# ESP32-H21 register map
Vendor: ESPRESSIF SYSTEMS (SHANGHAI) CO., LTD.; Series: ESP32 H-Series; File version: 1
CPU: RV32IMAC r0p0, little endian, no MPU, no FPU, 0 interrupt priority bits
Address unit: 32 bits
Registers are 32-bit, read-write, reset 0x0 unless marked. A register's access mark holds for its fields unless they carry their own. Offsets are from the block's base; [hi:lo] are bit positions; {n}, {i} and the like mark numbered series.

## LP_CLKRST — LP_CLKRST Peripheral
Base 0x600B0400
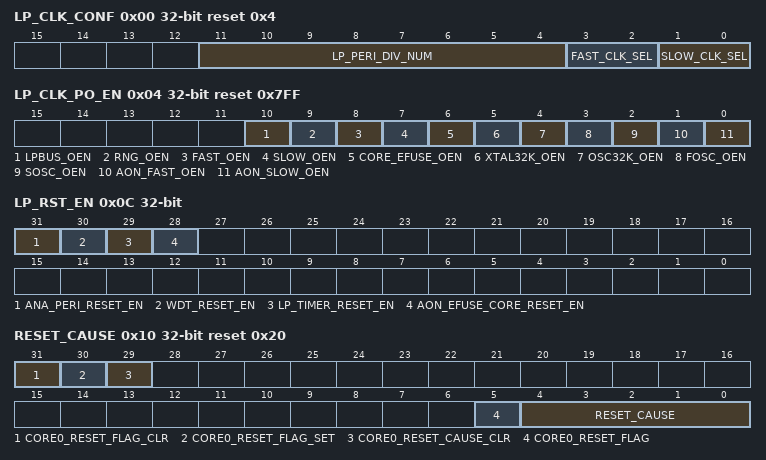
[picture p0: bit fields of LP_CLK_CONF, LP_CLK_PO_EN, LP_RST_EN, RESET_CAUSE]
0x00 LP_CLK_CONF reset 0x4 — need_des
  [11:4] LP_PERI_DIV_NUM — need_des
  [3:2] FAST_CLK_SEL — need_des
  [1:0] SLOW_CLK_SEL — need_des
0x04 LP_CLK_PO_EN reset 0x7FF — need_des
  [10] LPBUS_OEN — need_des
  [9] RNG_OEN — need_des
  [8] FAST_OEN — need_des
  [7] SLOW_OEN — need_des
  [6] CORE_EFUSE_OEN — need_des
  [5] XTAL32K_OEN — need_des
  [4] OSC32K_OEN — need_des
  [3] FOSC_OEN — need_des
  [2] SOSC_OEN — need_des
  [1] AON_FAST_OEN — need_des
  [0] AON_SLOW_OEN — need_des
0x08 LP_CLK_EN — need_des
  [31] FAST_ORI_GATE
0x0C LP_RST_EN — need_des
  [31] ANA_PERI_RESET_EN — need_des
  [30] WDT_RESET_EN — need_des
  [29] LP_TIMER_RESET_EN — need_des
  [28] AON_EFUSE_CORE_RESET_EN — need_des
0x10 RESET_CAUSE access per field reset 0x20 — need_des
  [31] CORE0_RESET_FLAG_CLR wo — need_des
  [30] CORE0_RESET_FLAG_SET wo — need_des
  [29] CORE0_RESET_CAUSE_CLR wo — need_des
  [5] CORE0_RESET_FLAG ro — need_des
  [4:0] RESET_CAUSE ro — need_des
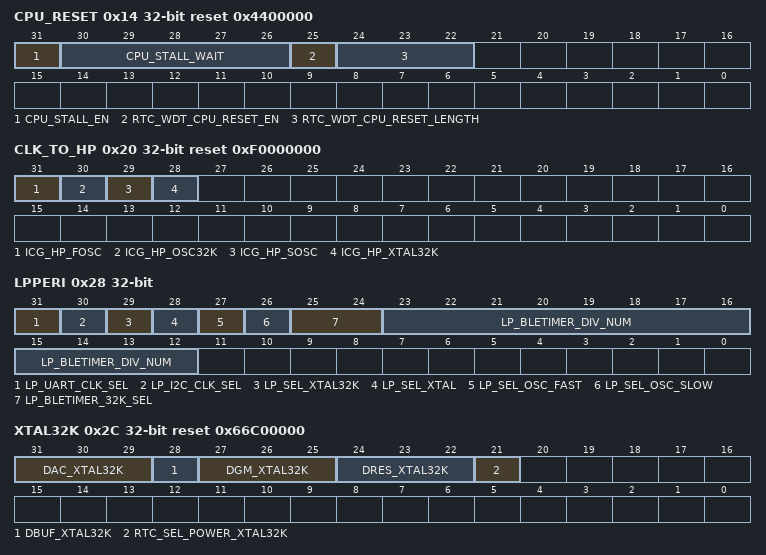
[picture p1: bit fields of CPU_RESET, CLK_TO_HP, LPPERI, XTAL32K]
0x14 CPU_RESET reset 0x4400000 — need_des
  [31] CPU_STALL_EN — need_des
  [30:26] CPU_STALL_WAIT — need_des
  [25] RTC_WDT_CPU_RESET_EN — need_des
  [24:22] RTC_WDT_CPU_RESET_LENGTH — need_des
0x18 FOSC_CNTL reset 0x96000000 — need_des
  [31:22] FOSC_DFREQ
0x1C RC32K_CNTL reset 0xA2800000 — need_des
  [31:22] RC32K_DFREQ
0x20 CLK_TO_HP reset 0xF0000000 — need_des
  [31] ICG_HP_FOSC — need_des
  [30] ICG_HP_OSC32K — need_des
  [29] ICG_HP_SOSC — need_des
  [28] ICG_HP_XTAL32K — need_des
0x24 LPMEM_FORCE — need_des
  [31] LPMEM_CLK_FORCE_ON
0x28 LPPERI — need_des
  [31] LP_UART_CLK_SEL — need_des
  [30] LP_I2C_CLK_SEL — need_des
  [29] LP_SEL_XTAL32K — need_des
  [28] LP_SEL_XTAL — need_des
  [27] LP_SEL_OSC_FAST — need_des
  [26] LP_SEL_OSC_SLOW — need_des
  [25:24] LP_BLETIMER_32K_SEL — need_des
  [23:12] LP_BLETIMER_DIV_NUM — need_des
0x2C XTAL32K reset 0x66C00000 — need_des
  [31:29] DAC_XTAL32K — need_des
  [28] DBUF_XTAL32K — need_des
  [27:25] DGM_XTAL32K — need_des
  [24:22] DRES_XTAL32K — need_des
  [21] RTC_SEL_POWER_XTAL32K — need_des
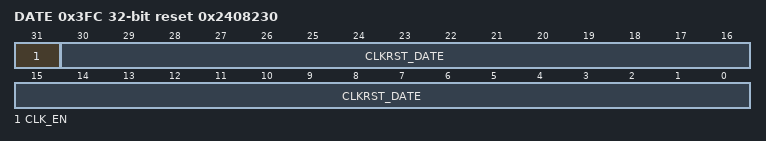
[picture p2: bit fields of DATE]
0x3FC DATE reset 0x2408230 — need_des
  [31] CLK_EN — need_des
  [30:0] CLKRST_DATE — need_des

## LP_TIMER — Low-power Timer
Base 0x600B0C00
0x00 TAR0_LOW — need_des
  [31:0] MAIN_TIMER_TAR_LOW0
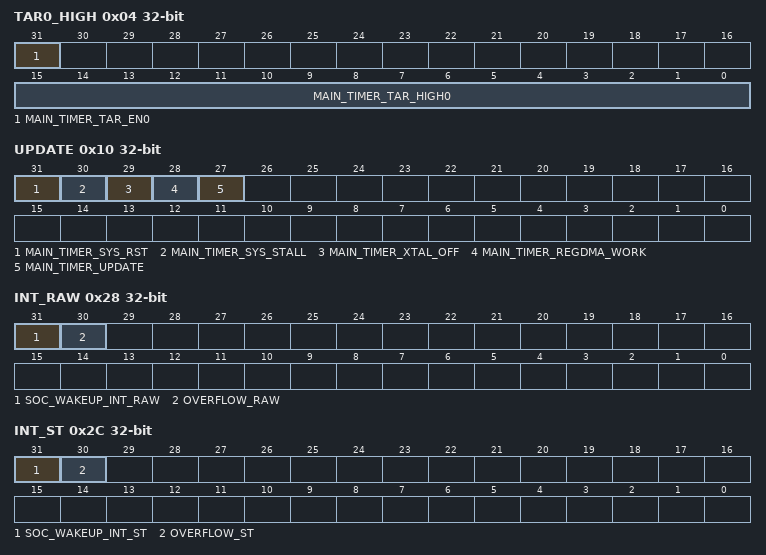
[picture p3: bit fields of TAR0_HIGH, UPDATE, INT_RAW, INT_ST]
0x04 TAR0_HIGH access per field — need_des
  [31] MAIN_TIMER_TAR_EN0 wo — need_des
  [15:0] MAIN_TIMER_TAR_HIGH0 rw — need_des
0x10 UPDATE access per field — need_des
  [31] MAIN_TIMER_SYS_RST rw — need_des
  [30] MAIN_TIMER_SYS_STALL rw — need_des
  [29] MAIN_TIMER_XTAL_OFF rw — need_des
  [28] MAIN_TIMER_REGDMA_WORK rw — Selects the triggering condition for the RTC timer,triggered when regdma working
  [27] MAIN_TIMER_UPDATE wo — need_des
0x14 MAIN_BUF0_LOW ro — need_des
  [31:0] MAIN_TIMER_BUF0_LOW
0x18 MAIN_BUF0_HIGH ro — need_des
  [15:0] MAIN_TIMER_BUF0_HIGH
0x1C MAIN_BUF1_LOW ro — need_des
  [31:0] MAIN_TIMER_BUF1_LOW
0x20 MAIN_BUF1_HIGH ro — need_des
  [15:0] MAIN_TIMER_BUF1_HIGH
0x24 MAIN_OVERFLOW wo — need_des
  [31] MAIN_TIMER_ALARM_LOAD
0x28 INT_RAW — need_des
  [31] SOC_WAKEUP_INT_RAW — need_des
  [30] OVERFLOW_RAW — need_des
0x2C INT_ST ro — need_des
  [31] SOC_WAKEUP_INT_ST — need_des
  [30] OVERFLOW_ST — need_des
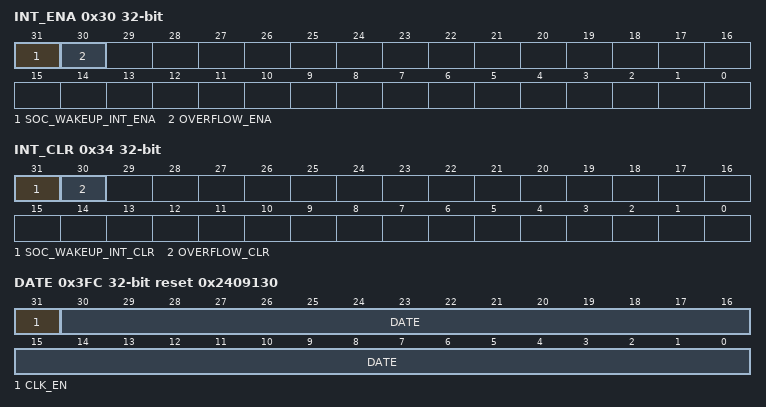
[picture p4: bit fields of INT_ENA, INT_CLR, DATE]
0x30 INT_ENA — need_des
  [31] SOC_WAKEUP_INT_ENA — need_des
  [30] OVERFLOW_ENA — need_des
0x34 INT_CLR wo — need_des
  [31] SOC_WAKEUP_INT_CLR — need_des
  [30] OVERFLOW_CLR — need_des
0x3FC DATE reset 0x2409130 — need_des
  [31] CLK_EN — need_des
  [30:0] DATE — need_des

## LP_WDT — Low-power Watchdog Timer
Base 0x600B1C00
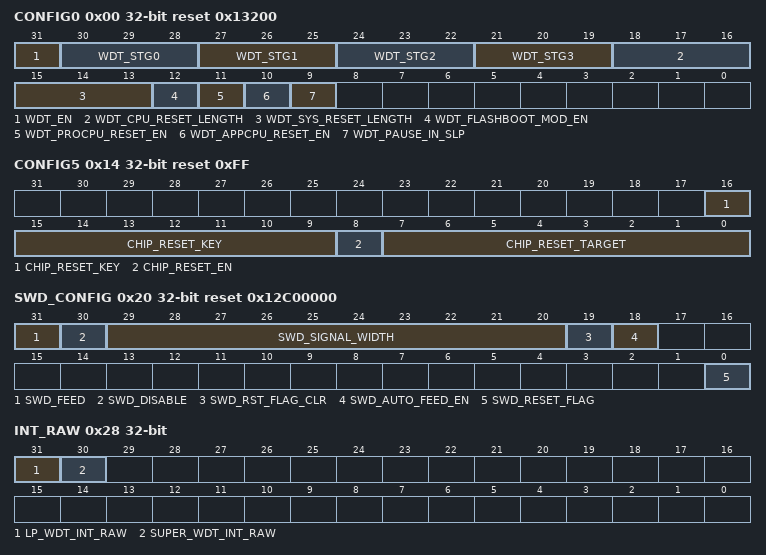
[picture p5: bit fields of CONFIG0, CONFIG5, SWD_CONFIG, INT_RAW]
0x00 CONFIG0 reset 0x13200 — need_des
  [31] WDT_EN — need_des
  [30-3n:28-3n] WDT_STG{n} (n=0..3) — need_des
  [18:16] WDT_CPU_RESET_LENGTH — need_des
  [15:13] WDT_SYS_RESET_LENGTH — need_des
  [12] WDT_FLASHBOOT_MOD_EN — need_des
  [11] WDT_PROCPU_RESET_EN — need_des
  [10] WDT_APPCPU_RESET_EN — need_des
  [9] WDT_PAUSE_IN_SLP — need_des
0x04 CONFIG1 reset 0x30D40 — need_des
  [31:0] WDT_STG0_HOLD
0x08 CONFIG2 reset 0x13880 — need_des
  [31:0] WDT_STG1_HOLD
0x0C CONFIG3 reset 0xFFF — need_des
  [31:0] WDT_STG2_HOLD
0x10 CONFIG4 reset 0xFFF — need_des
  [31:0] WDT_STG3_HOLD
0x14 CONFIG5 reset 0xFF — need_des
  [16:9] CHIP_RESET_KEY — need_des
  [8] CHIP_RESET_EN — need_des
  [7:0] CHIP_RESET_TARGET — need_des
0x18 FEED wo — need_des
  [31] RTC_WDT_FEED
0x1C WPROTECT — need_des
  [31:0] WDT_WKEY
0x20 SWD_CONFIG access per field reset 0x12C00000 — need_des
  [31] SWD_FEED wo — need_des
  [30] SWD_DISABLE rw — need_des
  [29:20] SWD_SIGNAL_WIDTH rw — need_des
  [19] SWD_RST_FLAG_CLR wo — need_des
  [18] SWD_AUTO_FEED_EN rw — need_des
  [0] SWD_RESET_FLAG ro — need_des
0x24 SWD_WPROTECT — need_des
  [31:0] SWD_WKEY
0x28 INT_RAW — need_des
  [31] LP_WDT_INT_RAW — need_des
  [30] SUPER_WDT_INT_RAW — need_des
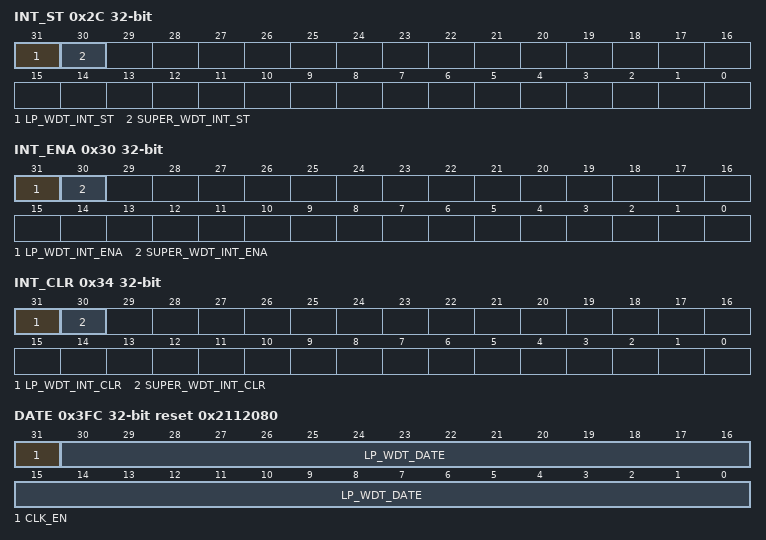
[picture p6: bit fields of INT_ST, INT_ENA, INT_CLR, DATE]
0x2C INT_ST ro — need_des
  [31] LP_WDT_INT_ST — need_des
  [30] SUPER_WDT_INT_ST — need_des
0x30 INT_ENA — need_des
  [31] LP_WDT_INT_ENA — need_des
  [30] SUPER_WDT_INT_ENA — need_des
0x34 INT_CLR wo — need_des
  [31] LP_WDT_INT_CLR — need_des
  [30] SUPER_WDT_INT_CLR — need_des
0x3FC DATE reset 0x2112080 — need_des
  [31] CLK_EN — need_des
  [30:0] LP_WDT_DATE — need_des
